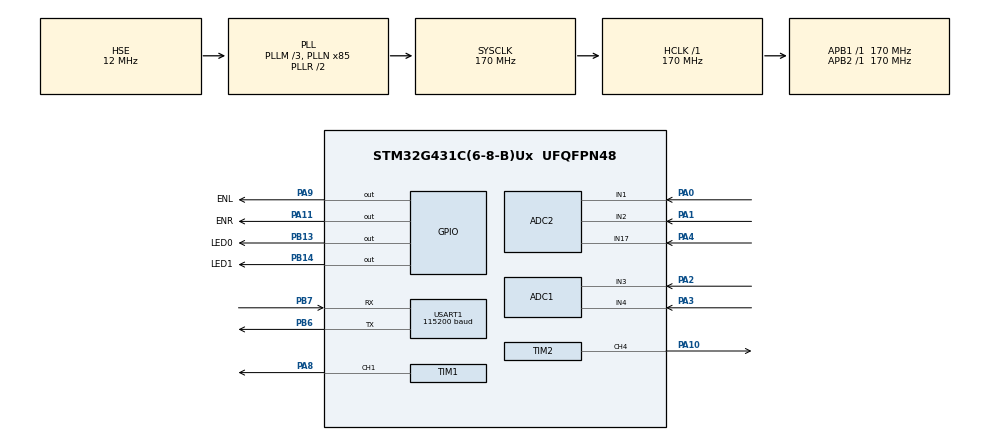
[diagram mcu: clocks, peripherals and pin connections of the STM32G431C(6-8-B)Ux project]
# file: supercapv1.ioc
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ADC1.Channel-0\#ChannelRegularConversion=ADC_CHANNEL_3
ADC1.Channel-1\#ChannelRegularConversion=ADC_CHANNEL_4
ADC1.Channel-2\#ChannelRegularConversion=ADC_CHANNEL_VREFINT
ADC1.DMAContinuousRequests=ENABLE
ADC1.DiscontinuousConvMode=ENABLE
ADC1.EOCSelection=ADC_EOC_SEQ_CONV
ADC1.ExternalTrigConv=ADC_EXTERNALTRIG_T3_TRGO
ADC1.NbrOfConversion=3
ADC1.NbrOfConversionFlag=1
ADC1.NbrOfDiscConversion=3
ADC1.OffsetNumber-0\#ChannelRegularConversion=ADC_OFFSET_NONE
ADC1.OffsetNumber-1\#ChannelRegularConversion=ADC_OFFSET_NONE
ADC1.OffsetNumber-2\#ChannelRegularConversion=ADC_OFFSET_NONE
ADC1.Rank-0\#ChannelRegularConversion=1
ADC1.Rank-1\#ChannelRegularConversion=2
ADC1.Rank-2\#ChannelRegularConversion=3
ADC1.SamplingTime-0\#ChannelRegularConversion=ADC_SAMPLETIME_47CYCLES_5
ADC1.SamplingTime-1\#ChannelRegularConversion=ADC_SAMPLETIME_6CYCLES_5
ADC1.SamplingTime-2\#ChannelRegularConversion=ADC_SAMPLETIME_6CYCLES_5
ADC1.master=1
ADC2.Channel-0\#ChannelRegularConversion=ADC_CHANNEL_1
ADC2.Channel-1\#ChannelRegularConversion=ADC_CHANNEL_2
ADC2.Channel-2\#ChannelRegularConversion=ADC_CHANNEL_17
ADC2.DMAContinuousRequests=ENABLE
ADC2.DiscontinuousConvMode=ENABLE
ADC2.EOCSelection=ADC_EOC_SEQ_CONV
ADC2.ExternalTrigConv=ADC_EXTERNALTRIG_T3_TRGO
ADC2.NbrOfConversion=3
ADC2.NbrOfConversionFlag=1
ADC2.NbrOfDiscConversion=3
ADC2.OffsetNumber-0\#ChannelRegularConversion=ADC_OFFSET_NONE
ADC2.OffsetNumber-1\#ChannelRegularConversion=ADC_OFFSET_NONE
ADC2.OffsetNumber-2\#ChannelRegularConversion=ADC_OFFSET_NONE
ADC2.Rank-0\#ChannelRegularConversion=1
ADC2.Rank-1\#ChannelRegularConversion=2
ADC2.Rank-2\#ChannelRegularConversion=3
ADC2.SamplingTime-0\#ChannelRegularConversion=ADC_SAMPLETIME_6CYCLES_5
ADC2.SamplingTime-1\#ChannelRegularConversion=ADC_SAMPLETIME_24CYCLES_5
ADC2.SamplingTime-2\#ChannelRegularConversion=ADC_SAMPLETIME_12CYCLES_5
Dma.ADC1.1.Direction=DMA_PERIPH_TO_MEMORY
Dma.ADC1.1.EventEnable=DISABLE
Dma.ADC1.1.Instance=DMA1_Channel2
Dma.ADC1.1.MemDataAlignment=DMA_MDATAALIGN_HALFWORD
Dma.ADC1.1.MemInc=DMA_MINC_ENABLE
Dma.ADC1.1.Mode=DMA_CIRCULAR
Dma.ADC1.1.PeriphDataAlignment=DMA_PDATAALIGN_HALFWORD
Dma.ADC1.1.PeriphInc=DMA_PINC_DISABLE
Dma.ADC1.1.Polarity=HAL_DMAMUX_REQ_GEN_RISING
Dma.ADC1.1.Priority=DMA_PRIORITY_HIGH
Dma.ADC1.1.RequestNumber=1
Dma.ADC1.1.SignalID=NONE
Dma.ADC1.1.SyncEnable=DISABLE
Dma.ADC1.1.SyncPolarity=HAL_DMAMUX_SYNC_NO_EVENT
Dma.ADC1.1.SyncRequestNumber=1
Dma.ADC1.1.SyncSignalID=NONE
Dma.ADC2.2.Direction=DMA_PERIPH_TO_MEMORY
Dma.ADC2.2.EventEnable=DISABLE
Dma.ADC2.2.Instance=DMA1_Channel3
Dma.ADC2.2.MemDataAlignment=DMA_MDATAALIGN_HALFWORD
Dma.ADC2.2.MemInc=DMA_MINC_ENABLE
Dma.ADC2.2.Mode=DMA_CIRCULAR
Dma.ADC2.2.PeriphDataAlignment=DMA_PDATAALIGN_HALFWORD
Dma.ADC2.2.PeriphInc=DMA_PINC_DISABLE
Dma.ADC2.2.Polarity=HAL_DMAMUX_REQ_GEN_RISING
Dma.ADC2.2.Priority=DMA_PRIORITY_HIGH
Dma.ADC2.2.RequestNumber=1
Dma.ADC2.2.SignalID=NONE
Dma.ADC2.2.SyncEnable=DISABLE
Dma.ADC2.2.SyncPolarity=HAL_DMAMUX_SYNC_NO_EVENT
Dma.ADC2.2.SyncRequestNumber=1
Dma.ADC2.2.SyncSignalID=NONE
Dma.Request0=USART1_TX
Dma.Request1=ADC1
Dma.Request2=ADC2
Dma.USART1_TX.0.Direction=DMA_MEMORY_TO_PERIPH
Dma.USART1_TX.0.EventEnable=DISABLE
Dma.USART1_TX.0.Instance=DMA1_Channel1
Dma.USART1_TX.0.MemDataAlignment=DMA_MDATAALIGN_BYTE
Dma.USART1_TX.0.MemInc=DMA_MINC_ENABLE
Dma.USART1_TX.0.Mode=DMA_CIRCULAR
Dma.USART1_TX.0.PeriphDataAlignment=DMA_PDATAALIGN_BYTE
Dma.USART1_TX.0.PeriphInc=DMA_PINC_DISABLE
Dma.USART1_TX.0.Polarity=HAL_DMAMUX_REQ_GEN_RISING
Dma.USART1_TX.0.Priority=DMA_PRIORITY_LOW
Dma.USART1_TX.0.RequestNumber=1
Dma.USART1_TX.0.SignalID=NONE
Dma.USART1_TX.0.SyncEnable=DISABLE
Dma.USART1_TX.0.SyncPolarity=HAL_DMAMUX_SYNC_NO_EVENT
Dma.USART1_TX.0.SyncRequestNumber=1
Dma.USART1_TX.0.SyncSignalID=NONE
Mcu.Family=STM32G4
Mcu.Name=STM32G431C(6-8-B)Ux
Mcu.Package=UFQFPN48
NVIC.PriorityGroup=NVIC_PRIORITYGROUP_4
NVIC.TIM2_IRQn=true\:5\:0\:true\:false\:true\:true\:true\:true
PA0.Mode=IN1-Single-Ended
PA0.Signal=ADC2_IN1
PA1.Mode=IN2-Single-Ended
PA1.Signal=ADC2_IN2
PA10.GPIO_Speed=GPIO_SPEED_FREQ_MEDIUM
PA10.Signal=S_TIM2_CH4
PA11.GPIO_Label=ENR
PA11.Signal=GPIO_Output
PA13.Mode=Serial_Wire
PA13.Signal=SYS_JTMS-SWDIO
PA14.Mode=Serial_Wire
PA14.Signal=SYS_JTCK-SWCLK
PA2.Mode=IN3-Single-Ended
PA2.Signal=ADC1_IN3
PA3.Mode=IN4-Single-Ended
PA3.Signal=ADC1_IN4
PA4.Mode=IN17-Single-Ended
PA4.Signal=ADC2_IN17
PA8.GPIO_Speed=GPIO_SPEED_FREQ_MEDIUM
PA8.Signal=S_TIM1_CH1
PA9.GPIO_Label=ENL
PA9.Signal=GPIO_Output
PB13.GPIO_Label=LED0
PB13.GPIO_Speed=GPIO_SPEED_FREQ_MEDIUM
PB13.Signal=GPIO_Output
PB14.GPIO_Label=LED1
PB14.GPIO_Speed=GPIO_SPEED_FREQ_MEDIUM
PB14.PinState=GPIO_PIN_SET
PB14.Signal=GPIO_Output
PB6.Mode=Asynchronous
PB6.Signal=USART1_TX
PB7.Mode=Asynchronous
PB7.Signal=USART1_RX
PF0-OSC_IN.Mode=HSE-External-Oscillator
PF0-OSC_IN.Signal=RCC_OSC_IN
PF1-OSC_OUT.Mode=HSE-External-Oscillator
PF1-OSC_OUT.Signal=RCC_OSC_OUT
ProjectManager.HeapSize=0x200
ProjectManager.StackSize=0x400
ProjectManager.TargetToolchain=Makefile
RCC.ADC12Freq_Value=170000000
RCC.AHBFreq_Value=170000000
RCC.APB1Freq_Value=170000000
RCC.APB1TimFreq_Value=170000000
RCC.APB2Freq_Value=170000000
RCC.APB2TimFreq_Value=170000000
RCC.CortexFreq_Value=170000000
RCC.EXTERNAL_CLOCK_VALUE=12288000
RCC.HCLKFreq_Value=170000000
RCC.HSE_VALUE=12000000
RCC.HSI48_VALUE=48000000
RCC.HSI_VALUE=16000000
RCC.LSE_VALUE=32768
RCC.PLLM=RCC_PLLM_DIV3
RCC.PLLN=85
RCC.PLLSourceVirtual=RCC_PLLSOURCE_HSE
RCC.SYSCLKFreq_VALUE=170000000
RCC.SYSCLKSource=RCC_SYSCLKSOURCE_PLLCLK
RCC.USBFreq_Value=170000000
RCC.VCOOutputFreq_Value=340000000
SH.S_TIM1_CH1.0=TIM1_CH1,PWM Generation1 CH1
SH.S_TIM2_CH4.0=TIM2_CH4,PWM Generation4 CH4
TIM1.Channel-PWM\ Generation1\ CH1=TIM_CHANNEL_1
TIM1.PeriodNoDither=399
TIM1.PulseNoDither_1=50
TIM2.Channel-PWM\ Generation4\ CH4=TIM_CHANNEL_4
TIM2.PeriodNoDither=399
TIM2.PulseNoDither_4=50
TIM3.PeriodNoDither=399
TIM3.TIM_MasterOutputTrigger=TIM_TRGO_UPDATE
USART1.BaudRate=115200
USART1.VirtualMode-Asynchronous=VM_ASYNC
VP_ADC1_Vref_Input.Mode=IN-Vrefint
VP_SYS_VS_DBSignals.Mode=DisableDeadBatterySignals
VP_TIM1_VS_ClockSourceINT.Mode=Internal
VP_TIM2_VS_ClockSourceINT.Mode=Internal
VP_TIM3_VS_ClockSourceINT.Mode=Internal
board=custom

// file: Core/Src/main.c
/* USER CODE BEGIN Header */
/**
  ******************************************************************************
  * @file           : main.c
  * @brief          : Main program body
  ******************************************************************************
  * @attention
  *
  * Copyright (c) 2024 STMicroelectronics.
  * All rights reserved.
  *
  * This software is licensed under terms that can be found in the LICENSE file
  * in the root directory of this software component.
  * If no LICENSE file comes with this software, it is provided AS-IS.
  *
  ******************************************************************************
  */
/* USER CODE END Header */
#include "main.h"
#include "adc.h"
#include "dma.h"
#include "tim.h"
#include "usart.h"
#include "gpio.h"

/* USER CODE BEGIN Includes */
#include "pwrctl.h"
/* USER CODE END Includes */

void SystemClock_Config(void);

int main(void)
{

  /* MCU Configuration--------------------------------------------------------*/

  /* Reset of all peripherals, Initializes the Flash interface and the Systick. */
  HAL_Init();

  /* Configure the system clock */
  SystemClock_Config();

  /* Initialize all configured peripherals */
  MX_GPIO_Init();
  MX_DMA_Init();
  MX_TIM1_Init();
  MX_TIM2_Init();
  MX_USART1_UART_Init();
  MX_ADC1_Init();
  MX_ADC2_Init();
  MX_TIM3_Init();
  /* USER CODE BEGIN 2 */
  HAL_ADCEx_Calibration_Start(&hadc1, ADC_SINGLE_ENDED);
  HAL_ADCEx_Calibration_Start(&hadc2, ADC_SINGLE_ENDED);
  pwrctl_init();
  /* USER CODE END 2 */

  /* Infinite loop */
  /* USER CODE BEGIN WHILE */
  while (1)
  {
    // setTargetCurrent(4.0f);
    // HAL_Delay(5);
    // setTargetCurrent(0.5f);
    // HAL_Delay(10);
    // setTargetCurrent(1.0f);
    // HAL_Delay(5);
    /* USER CODE END WHILE */

  }
}

void SystemClock_Config(void)
{
  RCC_OscInitTypeDef RCC_OscInitStruct = {0};
  RCC_ClkInitTypeDef RCC_ClkInitStruct = {0};

  /** Configure the main internal regulator output voltage
  */
  HAL_PWREx_ControlVoltageScaling(PWR_REGULATOR_VOLTAGE_SCALE1_BOOST);

  /** Initializes the RCC Oscillators according to the specified parameters
  * in the RCC_OscInitTypeDef structure.
  */
  RCC_OscInitStruct.OscillatorType = RCC_OSCILLATORTYPE_HSE;
  RCC_OscInitStruct.HSEState = RCC_HSE_ON;
  RCC_OscInitStruct.PLL.PLLState = RCC_PLL_ON;
  RCC_OscInitStruct.PLL.PLLSource = RCC_PLLSOURCE_HSE;
  RCC_OscInitStruct.PLL.PLLM = RCC_PLLM_DIV3;
  RCC_OscInitStruct.PLL.PLLN = 85;
  RCC_OscInitStruct.PLL.PLLP = RCC_PLLP_DIV2;
  RCC_OscInitStruct.PLL.PLLQ = RCC_PLLQ_DIV2;
  RCC_OscInitStruct.PLL.PLLR = RCC_PLLR_DIV2;
  if (HAL_RCC_OscConfig(&RCC_OscInitStruct) != HAL_OK)
  {
    Error_Handler();
  }

  /** Initializes the CPU, AHB and APB buses clocks
  */
  RCC_ClkInitStruct.ClockType = RCC_CLOCKTYPE_HCLK|RCC_CLOCKTYPE_SYSCLK
                              |RCC_CLOCKTYPE_PCLK1|RCC_CLOCKTYPE_PCLK2;
  RCC_ClkInitStruct.SYSCLKSource = RCC_SYSCLKSOURCE_PLLCLK;
  RCC_ClkInitStruct.AHBCLKDivider = RCC_SYSCLK_DIV1;
  RCC_ClkInitStruct.APB1CLKDivider = RCC_HCLK_DIV1;
  RCC_ClkInitStruct.APB2CLKDivider = RCC_HCLK_DIV1;

  if (HAL_RCC_ClockConfig(&RCC_ClkInitStruct, FLASH_LATENCY_4) != HAL_OK)
  {
    Error_Handler();
  }
}

void Error_Handler(void)
{
  __disable_irq();
  while (1)
  {
  }
}
